AUTOSAR XML (schema 4-0-3)
package /ComponentTypes
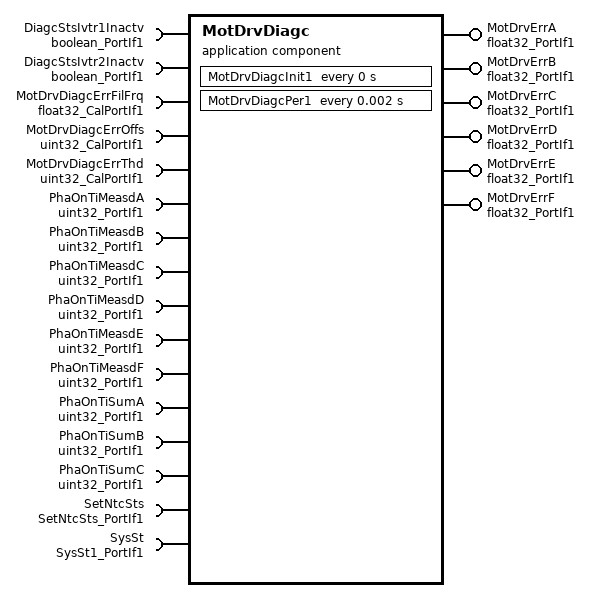
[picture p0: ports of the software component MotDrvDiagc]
  application sw component type MotDrvDiagc
    6 x provide port, all with nonqueued-sender-com-spec{data-element=Val, init-value=0}, provided-interface=float32_PortIf1:
      MotDrvErrA
      MotDrvErrB
      MotDrvErrC
      MotDrvErrD
      MotDrvErrE
      MotDrvErrF
    16 x require port:
      DiagcStsIvtr1Inactv: nonqueued-receiver-com-spec{data-element=Logl, filter=data-filter-type=ALWAYS, init-value=0}, required-interface=boolean_PortIf1
      DiagcStsIvtr2Inactv: nonqueued-receiver-com-spec{data-element=Logl, filter=data-filter-type=ALWAYS, init-value=0}, required-interface=boolean_PortIf1
      MotDrvDiagcErrFilFrq: parameter-require-com-spec{init-value=1.8, parameter=Val}, required-interface=float32_CalPortIf1
      MotDrvDiagcErrOffs: parameter-require-com-spec{init-value=0, parameter=Val}, required-interface=uint32_CalPortIf1
      MotDrvDiagcErrThd: parameter-require-com-spec{init-value=180000, parameter=Val}, required-interface=uint32_CalPortIf1
      PhaOnTiMeasdA: nonqueued-receiver-com-spec{data-element=Val, filter=data-filter-type=ALWAYS, init-value=0}, required-interface=uint32_PortIf1
      PhaOnTiMeasdB: nonqueued-receiver-com-spec{data-element=Val, filter=data-filter-type=ALWAYS, init-value=0}, required-interface=uint32_PortIf1
      PhaOnTiMeasdC: nonqueued-receiver-com-spec{data-element=Val, filter=data-filter-type=ALWAYS, init-value=0}, required-interface=uint32_PortIf1
      PhaOnTiMeasdD: nonqueued-receiver-com-spec{data-element=Val, filter=data-filter-type=ALWAYS, init-value=0}, required-interface=uint32_PortIf1
      PhaOnTiMeasdE: nonqueued-receiver-com-spec{data-element=Val, filter=data-filter-type=ALWAYS, init-value=0}, required-interface=uint32_PortIf1
      PhaOnTiMeasdF: nonqueued-receiver-com-spec{data-element=Val, filter=data-filter-type=ALWAYS, init-value=0}, required-interface=uint32_PortIf1
      PhaOnTiSumA: nonqueued-receiver-com-spec{data-element=Val, filter=data-filter-type=ALWAYS, init-value=0}, required-interface=uint32_PortIf1
      PhaOnTiSumB: nonqueued-receiver-com-spec{data-element=Val, filter=data-filter-type=ALWAYS, init-value=0}, required-interface=uint32_PortIf1
      PhaOnTiSumC: nonqueued-receiver-com-spec{data-element=Val, filter=data-filter-type=ALWAYS, init-value=0}, required-interface=uint32_PortIf1
      SetNtcSts: required-interface=SetNtcSts_PortIf1
      SysSt: nonqueued-receiver-com-spec{data-element=Val, filter=data-filter-type=ALWAYS, init-value=3}, required-interface=SysSt1_PortIf1
    behavior MotDrvDiagc_InternalBehavior
      ar-typed-per-instance-memorys:
        10 x data, all with sw-calibration-access=READ-ONLY:
          MotDrvDiagcPhaAFilLp: type=FilLpRec1
          MotDrvDiagcPhaBFilLp: type=FilLpRec1
          MotDrvDiagcPhaCFilLp: type=FilLpRec1
          MotDrvDiagcPhaDFilLp: type=FilLpRec1
          MotDrvDiagcPhaEFilLp: type=FilLpRec1
          MotDrvDiagcPhaFFilLp: type=FilLpRec1
          MotDrvDiagcPhaOnTiSumAPrev: type=uint32
          MotDrvDiagcPhaOnTiSumBPrev: type=uint32
          MotDrvDiagcPhaOnTiSumCPrev: type=uint32
          UnitDly: type=boolean
      timing event MotDrvDiagc_InitEvent: start-on-event=MotDrvDiagcInit1, period=0
      timing event TMT_MotDrvDiagcPer1: start-on-event=MotDrvDiagcPer1, period=0.002
      runnable MotDrvDiagcInit1
      runnable MotDrvDiagcPer1
        data-receive-point-by-arguments:
          12 x access:
            REC_DiagcStsIvtr1Inactv_Logl: accessed-variable=DiagcStsIvtr1Inactv.Logl
            REC_DiagcStsIvtr2Inactv_Logl: accessed-variable=DiagcStsIvtr2Inactv.Logl
            REC_MotCtrlPhaOnTiSumA_Val: accessed-variable=PhaOnTiSumA.Val
            REC_MotCtrlPhaOnTiSumB_Val: accessed-variable=PhaOnTiSumB.Val
            REC_MotCtrlPhaOnTiSumC_Val: accessed-variable=PhaOnTiSumC.Val
            REC_PhaOnTiMeasdA_Val: accessed-variable=PhaOnTiMeasdA.Val
            REC_PhaOnTiMeasdB_Val: accessed-variable=PhaOnTiMeasdB.Val
            REC_PhaOnTiMeasdC_Val: accessed-variable=PhaOnTiMeasdC.Val
            REC_PhaOnTiMeasdD_Val: accessed-variable=PhaOnTiMeasdD.Val
            REC_PhaOnTiMeasdE_Val: accessed-variable=PhaOnTiMeasdE.Val
            REC_PhaOnTiMeasdF_Val: accessed-variable=PhaOnTiMeasdF.Val
            REC_SysSt_Val: accessed-variable=SysSt.Val
        data-send-points:
          6 x access:
            SEND_MotDrvErrA_Val: accessed-variable=MotDrvErrA.Val
            SEND_MotDrvErrB_Val: accessed-variable=MotDrvErrB.Val
            SEND_MotDrvErrC_Val: accessed-variable=MotDrvErrC.Val
            SEND_MotDrvErrD_Val: accessed-variable=MotDrvErrD.Val
            SEND_MotDrvErrE_Val: accessed-variable=MotDrvErrE.Val
            SEND_MotDrvErrF_Val: accessed-variable=MotDrvErrF.Val
        sync call SC_SetNtcSts_Oper: operation=SetNtcSts.Oper, timeout=0
  swc implementation MotDrvDiagc_Implementation: behavior=MotDrvDiagc_InternalBehavior
    code-descriptors:
      code Default: artifact-descriptors=autosar-engineering-object={short-label=Default, category=SWSRC}
